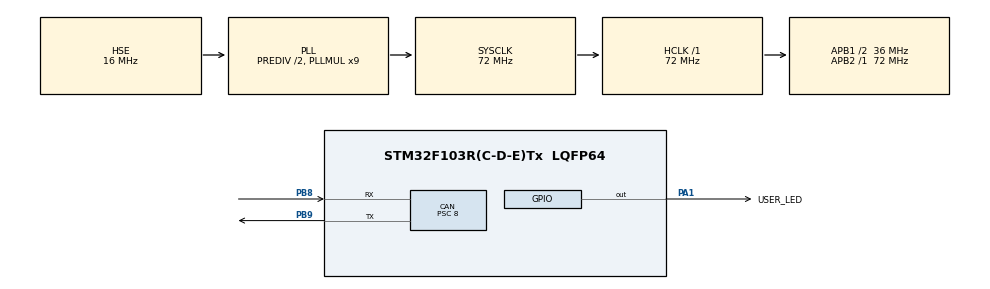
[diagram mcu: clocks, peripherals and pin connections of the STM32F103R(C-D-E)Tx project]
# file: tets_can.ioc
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CAN.BS1=CAN_BS1_4TQ
CAN.BS2=CAN_BS2_4TQ
CAN.CalculateBaudRate=500000
CAN.CalculateTimeBit=2000
CAN.CalculateTimeQuantum=222.22222222222223
CAN.Prescaler=8
Mcu.Family=STM32F1
Mcu.Name=STM32F103R(C-D-E)Tx
Mcu.Package=LQFP64
NVIC.PriorityGroup=NVIC_PRIORITYGROUP_4
PA1.GPIO_Label=USER_LED
PA1.Signal=GPIO_Output
PB8.Mode=CAN_Activate
PB8.Signal=CAN_RX
PB9.Mode=CAN_Activate
PB9.Signal=CAN_TX
PC14-OSC32_IN.Mode=LSE-External-Oscillator
PC14-OSC32_IN.Signal=RCC_OSC32_IN
PC15-OSC32_OUT.Mode=LSE-External-Oscillator
PC15-OSC32_OUT.Signal=RCC_OSC32_OUT
PD0-OSC_IN.Mode=HSE-External-Oscillator
PD0-OSC_IN.Signal=RCC_OSC_IN
PD1-OSC_OUT.Mode=HSE-External-Oscillator
PD1-OSC_OUT.Signal=RCC_OSC_OUT
ProjectManager.HeapSize=0x200
ProjectManager.StackSize=0x400
ProjectManager.TargetToolchain=STM32CubeIDE
RCC.AHBFreq_Value=72000000
RCC.APB1CLKDivider=RCC_HCLK_DIV2
RCC.APB1Freq_Value=36000000
RCC.APB1TimFreq_Value=72000000
RCC.APB2Freq_Value=72000000
RCC.APB2TimFreq_Value=72000000
RCC.HCLKFreq_Value=72000000
RCC.HSEDivPLL=RCC_HSE_PREDIV_DIV2
RCC.HSE_VALUE=16000000
RCC.PLLMUL=RCC_PLL_MUL9
RCC.PLLSourceVirtual=RCC_PLLSOURCE_HSE
RCC.PREFETCH_ENABLE=1
RCC.SYSCLKFreq_VALUE=72000000
RCC.SYSCLKSource=RCC_SYSCLKSOURCE_PLLCLK
RCC.USBFreq_Value=72000000
VP_SYS_VS_ND.Mode=No_Debug
board=custom

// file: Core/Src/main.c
/* USER CODE BEGIN Header */
/**
  ******************************************************************************
  * @file           : main.c
  * @brief          : Main program body
  ******************************************************************************
  * @attention
  *
  * Copyright (c) 2024 STMicroelectronics.
  * All rights reserved.
  *
  * This software is licensed under terms that can be found in the LICENSE file
  * in the root directory of this software component.
  * If no LICENSE file comes with this software, it is provided AS-IS.
  *
  ******************************************************************************
  */
/* USER CODE END Header */
#include "main.h"
#include "can.h"
#include "gpio.h"

/* USER CODE BEGIN Includes */
#include <stdint.h>
/* USER CODE END Includes */

/* USER CODE BEGIN PV */
CAN_FilterTypeDef CAN_filter0;
CAN_FilterTypeDef CAN_filter1;
CAN_FilterTypeDef CAN_filter2;
/* USER CODE END PV */

void SystemClock_Config(void);

int main(void)
{

  /* MCU Configuration--------------------------------------------------------*/

  /* Reset of all peripherals, Initializes the Flash interface and the Systick. */
  HAL_Init();

  /* Configure the system clock */
  SystemClock_Config();

  /* Initialize all configured peripherals */
  MX_GPIO_Init();
  MX_CAN_Init();
  /*   CODE BEGIN 2 */
  CanFilterSetup();
  HAL_CAN_Start(&hcan);

  /* USER CODE END 2 */

  /* Infinite loop */
  /* USER CODE BEGIN WHILE */

  /**
   * 	CAN message header for a drive command. This command header is to
   * 	send an appropriate drive command to the motor controller.
   */
  CAN_TxHeaderTypeDef drive_command_header = {
      .StdId = 0x401,
      .ExtId = 0x0000,
      .IDE = CAN_ID_STD,
      .RTR = CAN_RTR_DATA,
      .DLC = 8};

  while (1)
  {
    /* USER CODE END WHILE */

    /* USER CODE BEGIN 3 */
    uint8_t data_send[8];
    for (int i = 0; i < 8U; i++)
    {
      data_send[i] = 1;
    }

    if (HAL_CAN_GetTxMailboxesFreeLevel(&hcan) != 0U)
    {
      if (HAL_CAN_AddTxMessage(&hcan, &drive_command_header, &data_send[0], &can_mailbox) == HAL_OK) {
        HAL_GPIO_TogglePin(USER_LED_GPIO_Port, USER_LED_Pin);
      }
    }

    HAL_Delay(100);

  }
  /* USER CODE END 3 */
}

void SystemClock_Config(void)
{
  RCC_OscInitTypeDef RCC_OscInitStruct = {0};
  RCC_ClkInitTypeDef RCC_ClkInitStruct = {0};

  /** Initializes the RCC Oscillators according to the specified parameters
  * in the RCC_OscInitTypeDef structure.
  */
  RCC_OscInitStruct.OscillatorType = RCC_OSCILLATORTYPE_HSE;
  RCC_OscInitStruct.HSEState = RCC_HSE_ON;
  RCC_OscInitStruct.HSEPredivValue = RCC_HSE_PREDIV_DIV2;
  RCC_OscInitStruct.HSIState = RCC_HSI_ON;
  RCC_OscInitStruct.PLL.PLLState = RCC_PLL_ON;
  RCC_OscInitStruct.PLL.PLLSource = RCC_PLLSOURCE_HSE;
  RCC_OscInitStruct.PLL.PLLMUL = RCC_PLL_MUL9;
  if (HAL_RCC_OscConfig(&RCC_OscInitStruct) != HAL_OK)
  {
    Error_Handler();
  }

  /** Initializes the CPU, AHB and APB buses clocks
  */
  RCC_ClkInitStruct.ClockType = RCC_CLOCKTYPE_HCLK|RCC_CLOCKTYPE_SYSCLK
                              |RCC_CLOCKTYPE_PCLK1|RCC_CLOCKTYPE_PCLK2;
  RCC_ClkInitStruct.SYSCLKSource = RCC_SYSCLKSOURCE_PLLCLK;
  RCC_ClkInitStruct.AHBCLKDivider = RCC_SYSCLK_DIV1;
  RCC_ClkInitStruct.APB1CLKDivider = RCC_HCLK_DIV2;
  RCC_ClkInitStruct.APB2CLKDivider = RCC_HCLK_DIV1;

  if (HAL_RCC_ClockConfig(&RCC_ClkInitStruct, FLASH_LATENCY_2) != HAL_OK)
  {
    Error_Handler();
  }
}

void Error_Handler(void)
{
  __disable_irq();
  while (1)
  {
  }
}
